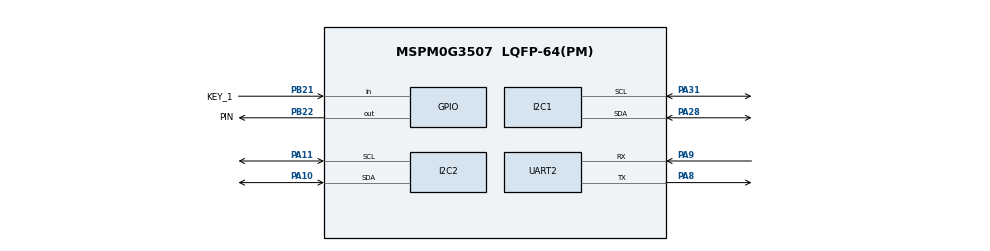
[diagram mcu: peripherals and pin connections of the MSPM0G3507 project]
/**
 * These arguments were used when this file was generated. They will be automatically applied on subsequent loads
 * via the GUI or CLI. Run CLI with '--help' for additional information on how to override these arguments.
 * @cliArgs --device "MSPM0G350X" --part "Default" --package "LQFP-64(PM)" --product "mspm0_sdk@2.02.00.05"
 * @v2CliArgs --device "MSPM0G3507" --package "LQFP-64(PM)" --product "mspm0_sdk@2.02.00.05"
 * @versions {"tool":"1.21.1+3772"}
 */

/**
 * Import the modules used in this configuration.
 */
const GPIO   = scripting.addModule("/ti/driverlib/GPIO", {}, false);
const GPIO1  = GPIO.addInstance();
const GPIO2  = GPIO.addInstance();
const I2C    = scripting.addModule("/ti/driverlib/I2C", {}, false);
const I2C1   = I2C.addInstance();
const I2C2   = I2C.addInstance();
const SYSCTL = scripting.addModule("/ti/driverlib/SYSCTL");
const TIMER  = scripting.addModule("/ti/driverlib/TIMER", {}, false);
const TIMER1 = TIMER.addInstance();
const TIMER2 = TIMER.addInstance();
const TIMER3 = TIMER.addInstance();
const UART   = scripting.addModule("/ti/driverlib/UART", {}, false);
const UART1  = UART.addInstance();
const UART2  = UART.addInstance();

/**
 * Write custom configuration values to the imported modules.
 */
const divider9       = system.clockTree["UDIV"];
divider9.divideValue = 2;

const mux4       = system.clockTree["EXHFMUX"];
mux4.inputSelect = "EXHFMUX_XTAL";

const mux8       = system.clockTree["HSCLKMUX"];
mux8.inputSelect = "HSCLKMUX_SYSPLL2X";

const mux12       = system.clockTree["SYSPLLMUX"];
mux12.inputSelect = "zSYSPLLMUX_HFCLK";

const pinFunction4        = system.clockTree["HFXT"];
pinFunction4.inputFreq    = 40;
pinFunction4.enable       = true;
pinFunction4.HFCLKMonitor = true;
pinFunction4.HFXTStartup  = 20;

GPIO1.$name                          = "LED";
GPIO1.associatedPins[0].$name        = "PIN";
GPIO1.associatedPins[0].ioStructure  = "SD";
GPIO1.associatedPins[0].assignedPort = "PORTB";
GPIO1.associatedPins[0].assignedPin  = "22";
GPIO1.associatedPins[0].pin.$assign  = "PB22";

const Board = scripting.addModule("/ti/driverlib/Board", {}, false);

GPIO2.$name                              = "KEY";
GPIO2.associatedPins.create(2);
GPIO2.associatedPins[0].$name            = "KEY_1";
GPIO2.associatedPins[0].direction        = "INPUT";
GPIO2.associatedPins[0].internalResistor = "PULL_UP";
GPIO2.associatedPins[0].pin.$assign      = "PB21";
GPIO2.associatedPins[1].$name            = "KEY_2";
GPIO2.associatedPins[1].direction        = "INPUT";
GPIO2.associatedPins[1].internalResistor = "PULL_UP";

I2C1.basicEnableController             = true;
I2C1.basicEnableTarget                 = true;
I2C1.basicControllerStandardBusSpeed   = "Fast";
I2C1.$name                             = "I2C_OLED";
I2C1.peripheral.$assign                = "I2C0";
I2C1.peripheral.sdaPin.$assign         = "PA28";
I2C1.peripheral.sclPin.$assign         = "PA31";
I2C1.sdaPinConfig.hideOutputInversion  = scripting.forceWrite(false);
I2C1.sdaPinConfig.onlyInternalResistor = scripting.forceWrite(false);
I2C1.sdaPinConfig.passedPeripheralType = scripting.forceWrite("Digital");
I2C1.sdaPinConfig.$name                = "ti_driverlib_gpio_GPIOPinGeneric4";
I2C1.sclPinConfig.hideOutputInversion  = scripting.forceWrite(false);
I2C1.sclPinConfig.onlyInternalResistor = scripting.forceWrite(false);
I2C1.sclPinConfig.passedPeripheralType = scripting.forceWrite("Digital");
I2C1.sclPinConfig.$name                = "ti_driverlib_gpio_GPIOPinGeneric5";

I2C2.$name                             = "I2C_MPU6050";
I2C2.basicEnableController             = true;
I2C2.basicControllerStandardBusSpeed   = "Fast";
I2C2.peripheral.sdaPin.$assign         = "PA10";
I2C2.peripheral.sclPin.$assign         = "PA11";
I2C2.sdaPinConfig.$name                = "ti_driverlib_gpio_GPIOPinGeneric2";
I2C2.sdaPinConfig.hideOutputInversion  = scripting.forceWrite(false);
I2C2.sdaPinConfig.onlyInternalResistor = scripting.forceWrite(false);
I2C2.sdaPinConfig.passedPeripheralType = scripting.forceWrite("Digital");
I2C2.sclPinConfig.$name                = "ti_driverlib_gpio_GPIOPinGeneric3";
I2C2.sclPinConfig.hideOutputInversion  = scripting.forceWrite(false);
I2C2.sclPinConfig.onlyInternalResistor = scripting.forceWrite(false);
I2C2.sclPinConfig.passedPeripheralType = scripting.forceWrite("Digital");

SYSCTL.forceDefaultClkConfig = true;
SYSCTL.clockTreeEn           = true;
SYSCTL.validateClkStatus     = true;

TIMER1.timerMode          = "PERIODIC";
TIMER1.timerClkPrescale   = 256;
TIMER1.interrupts         = ["ZERO"];
TIMER1.$name              = "TIMER_Key";
TIMER1.interruptPriority  = "3";
TIMER1.timerPeriod        = "1ms";
TIMER1.peripheral.$assign = "TIMA0";

TIMER2.$name              = "TIMER_1";
TIMER2.timerClkPrescale   = 100;
TIMER2.timerClkDiv        = 2;
TIMER2.interrupts         = ["ZERO"];
TIMER2.timerMode          = "PERIODIC";
TIMER2.timerPeriod        = "200ms";
TIMER2.timerStartTimer    = true;
TIMER2.peripheral.$assign = "TIMG8";

TIMER3.$name            = "TIMER_Gyro";
TIMER3.timerMode        = "PERIODIC";
TIMER3.timerStartTimer  = true;
TIMER3.timerClkPrescale = 100;
TIMER3.timerPeriod      = "20 ms";
TIMER3.interrupts       = ["ZERO"];

UART1.$name             = "UART_0";
UART1.txPinConfig.$name = "ti_driverlib_gpio_GPIOPinGeneric0";
UART1.rxPinConfig.$name = "ti_driverlib_gpio_GPIOPinGeneric1";

UART2.$name                            = "UART_OPMV";
UART2.peripheral.$assign               = "UART1";
UART2.peripheral.rxPin.$assign         = "PA9";
UART2.peripheral.txPin.$assign         = "PA8";
UART2.txPinConfig.$name                = "ti_driverlib_gpio_GPIOPinGeneric6";
UART2.txPinConfig.direction            = scripting.forceWrite("OUTPUT");
UART2.txPinConfig.hideOutputInversion  = scripting.forceWrite(false);
UART2.txPinConfig.onlyInternalResistor = scripting.forceWrite(false);
UART2.txPinConfig.passedPeripheralType = scripting.forceWrite("Digital");
UART2.rxPinConfig.$name                = "ti_driverlib_gpio_GPIOPinGeneric7";
UART2.rxPinConfig.hideOutputInversion  = scripting.forceWrite(false);
UART2.rxPinConfig.onlyInternalResistor = scripting.forceWrite(false);
UART2.rxPinConfig.passedPeripheralType = scripting.forceWrite("Digital");

/**
 * Pinmux solution for unlocked pins/peripherals. This ensures that minor changes to the automatic solver in a future
 * version of the tool will not impact the pinmux you originally saw.  These lines can be completely deleted in order to
 * re-solve from scratch.
 */
pinFunction4.peripheral.$suggestSolution           = "SYSCTL";
pinFunction4.peripheral.hfxInPin.$suggestSolution  = "PA5";
pinFunction4.peripheral.hfxOutPin.$suggestSolution = "PA6";
Board.peripheral.$suggestSolution                  = "DEBUGSS";
Board.peripheral.swclkPin.$suggestSolution         = "PA20";
Board.peripheral.swdioPin.$suggestSolution         = "PA19";
GPIO2.associatedPins[1].pin.$suggestSolution       = "PB13";
I2C2.peripheral.$suggestSolution                   = "I2C1";
TIMER3.peripheral.$suggestSolution                 = "TIMA1";
UART1.peripheral.$suggestSolution                  = "UART0";
UART1.peripheral.rxPin.$suggestSolution            = "PA1";
UART1.peripheral.txPin.$suggestSolution            = "PA0";
